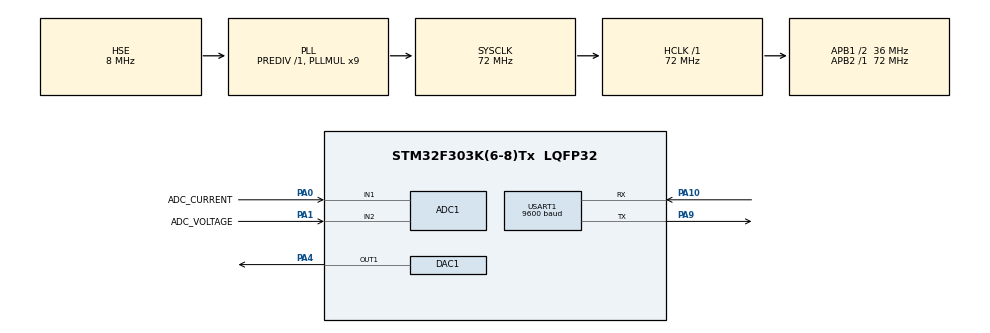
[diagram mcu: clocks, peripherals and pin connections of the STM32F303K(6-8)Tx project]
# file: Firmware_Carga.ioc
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ADC1.Channel-0\#ChannelRegularConversion=ADC_CHANNEL_1
ADC1.Channel-1\#ChannelRegularConversion=ADC_CHANNEL_2
ADC1.DMAContinuousRequests=ENABLE
ADC1.EnableInjectedConversion=DISABLE
ADC1.ExternalTrigConv=ADC_EXTERNALTRIGCONV_T1_TRGO
ADC1.NbrOfConversion=2
ADC1.NbrOfConversionFlag=1
ADC1.Offset-0\#ChannelRegularConversion=0
ADC1.Offset-1\#ChannelRegularConversion=0
ADC1.OffsetNumber-0\#ChannelRegularConversion=ADC_OFFSET_NONE
ADC1.OffsetNumber-1\#ChannelRegularConversion=ADC_OFFSET_NONE
ADC1.Rank-0\#ChannelRegularConversion=1
ADC1.Rank-1\#ChannelRegularConversion=2
ADC1.SamplingTime-0\#ChannelRegularConversion=ADC_SAMPLETIME_601CYCLES_5
ADC1.SamplingTime-1\#ChannelRegularConversion=ADC_SAMPLETIME_1CYCLE_5
ADC1.SamplingTimeOPAMP-1\#ChannelRegularConversion=ADC_SAMPLETIME_61CYCLES_5
ADC1.SubFamily=STM32F303x8
ADC1.master=1
DAC1.DAC_OutputBuffer=DAC_OUTPUTBUFFER_DISABLE
Dma.ADC1.0.Direction=DMA_PERIPH_TO_MEMORY
Dma.ADC1.0.Instance=DMA1_Channel1
Dma.ADC1.0.MemDataAlignment=DMA_MDATAALIGN_HALFWORD
Dma.ADC1.0.MemInc=DMA_MINC_ENABLE
Dma.ADC1.0.Mode=DMA_CIRCULAR
Dma.ADC1.0.PeriphDataAlignment=DMA_PDATAALIGN_HALFWORD
Dma.ADC1.0.PeriphInc=DMA_PINC_DISABLE
Dma.ADC1.0.Priority=DMA_PRIORITY_VERY_HIGH
Dma.Request0=ADC1
Mcu.Family=STM32F3
Mcu.Name=STM32F303K(6-8)Tx
Mcu.Package=LQFP32
NVIC.DMA1_Channel1_IRQn=true\:0\:0\:false\:false\:true\:false\:true
NVIC.PriorityGroup=NVIC_PRIORITYGROUP_4
PA0.GPIO_Label=ADC_CURRENT
PA0.Mode=IN1-Single-Ended
PA0.Signal=ADC1_IN1
PA1.GPIO_Label=ADC_VOLTAGE
PA1.Mode=IN2-Single-Ended
PA1.Signal=ADC1_IN2
PA10.Mode=Asynchronous
PA10.Signal=USART1_RX
PA13.Mode=Trace_Asynchronous_SW
PA13.Signal=SYS_JTMS-SWDIO
PA14.Mode=Trace_Asynchronous_SW
PA14.Signal=SYS_JTCK-SWCLK
PA4.Signal=COMP_DAC11_group
PA9.Mode=Asynchronous
PA9.Signal=USART1_TX
PB3.Mode=Trace_Asynchronous_SW
PB3.Signal=SYS_JTDO-TRACESWO
PF0\ /\ OSC_IN.Mode=HSE-External-Oscillator
PF0\ /\ OSC_IN.Signal=RCC_OSC_IN
PF1\ /\ OSC_OUT.Mode=HSE-External-Oscillator
PF1\ /\ OSC_OUT.Signal=RCC_OSC_OUT
ProjectManager.HeapSize=0x200
ProjectManager.StackSize=0x400
ProjectManager.TargetToolchain=EWARM V8
RCC.AHBFreq_Value=72000000
RCC.APB1CLKDivider=RCC_HCLK_DIV2
RCC.APB1Freq_Value=36000000
RCC.APB1TimFreq_Value=72000000
RCC.APB2Freq_Value=72000000
RCC.APB2TimFreq_Value=72000000
RCC.CortexFreq_Value=72000000
RCC.HCLKFreq_Value=72000000
RCC.HSE_VALUE=8000000
RCC.HSI_VALUE=8000000
RCC.PLLMUL=RCC_PLL_MUL9
RCC.PLLSourceVirtual=RCC_PLLSOURCE_HSE
RCC.SYSCLKFreq_VALUE=72000000
RCC.SYSCLKSourceVirtual=RCC_SYSCLKSOURCE_PLLCLK
SH.COMP_DAC11_group.0=DAC1_OUT1,DAC_OUT1
TIM1.Period=1
TIM1.Prescaler=720
TIM1.TIM_MasterOutputTrigger=TIM_TRGO_UPDATE
USART1.BaudRate=9600
USART1.Parity=PARITY_NONE
USART1.StopBits=STOPBITS_1
USART1.VirtualMode-Asynchronous=VM_ASYNC
USART1.WordLength=WORDLENGTH_8B
VP_TIM1_VS_ClockSourceINT.Mode=Internal
board=custom

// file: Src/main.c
/* USER CODE BEGIN Header */
/**
  ******************************************************************************
  * @file           : main.c
  * @brief          : Main program body
  ******************************************************************************
  * @attention
  *
  * <h2><center>&copy; Copyright (c) 2021 STMicroelectronics.
  * All rights reserved.</center></h2>
  *
  * This software component is licensed by ST under BSD 3-Clause license,
  * the "License"; You may not use this file except in compliance with the
  * License. You may obtain a copy of the License at:
  *                        opensource.org/licenses/BSD-3-Clause
  *
  ******************************************************************************
  */

/**

  ******************************************************************************
   *CORRENTE M�XIMA LIMITADA PELO DAC = 3.3 A
  ******************************************************************************

*/

/* USER CODE END Header */
#include "main.h"

/* USER CODE BEGIN Includes */
#include "stdbool.h"

/* USER CODE END Includes */

ADC_HandleTypeDef hadc1;
DMA_HandleTypeDef hdma_adc1;

DAC_HandleTypeDef hdac1;

TIM_HandleTypeDef htim1;

UART_HandleTypeDef huart1;

void SystemClock_Config(void);
static void MX_GPIO_Init(void);
static void MX_ADC1_Init(void);
static void MX_DAC1_Init(void);
static void MX_DMA_Init(void);
static void MX_USART1_UART_Init(void);
static void MX_TIM1_Init(void);

/* USER CODE BEGIN 0 */

E_Carga_State Carga_State = CURRENT;

uint16_t ADC_VALUES[2];

float current_Value_A = 0.25;
float potency_Value_W = 0;
float resistance_Value_Ohms = 0;

/* USER CODE END 0 */

int main(void)
{

  /* MCU Configuration--------------------------------------------------------*/

  /* Reset of all peripherals, Initializes the Flash interface and the Systick. */
  HAL_Init();

  /* Configure the system clock */
  SystemClock_Config();

  /* USER CODE BEGIN SysInit */
  MX_DMA_Init();
  /* USER CODE END SysInit */

  /* Initialize all configured peripherals */
  MX_GPIO_Init();
  MX_ADC1_Init();
  MX_DAC1_Init();
  MX_DMA_Init();
  MX_USART1_UART_Init();
  MX_TIM1_Init();
  /* USER CODE BEGIN 2 */

  HAL_ADCEx_Calibration_Start(&hadc1, ADC_SINGLE_ENDED);
  HAL_TIM_Base_Start(&htim1);
  HAL_ADC_Start_DMA(&hadc1, (uint32_t*) ADC_VALUES, 2);

  Load_State_Machine_Init();

  /* USER CODE END 2 */

  /* Infinite loop */
  /* USER CODE BEGIN WHILE */
  while (1)
  {
    /* PARA DEBUG IAR*/
    /*
    Load_State_Machine(Carga_State);

    set_Current_Value(current_Value_A);

    set_Potency_Value(potency_Value_W);

    set_Resistance_Value(resistance_Value_Ohms);
    */

    Load_State_Machine();

    /* USER CODE END WHILE */

  }
}

void SystemClock_Config(void)
{
  RCC_OscInitTypeDef RCC_OscInitStruct = {0};
  RCC_ClkInitTypeDef RCC_ClkInitStruct = {0};
  RCC_PeriphCLKInitTypeDef PeriphClkInit = {0};

  /** Initializes the RCC Oscillators according to the specified parameters
  * in the RCC_OscInitTypeDef structure.
  */
  RCC_OscInitStruct.OscillatorType = RCC_OSCILLATORTYPE_HSE;
  RCC_OscInitStruct.HSEState = RCC_HSE_ON;
  RCC_OscInitStruct.HSEPredivValue = RCC_HSE_PREDIV_DIV1;
  RCC_OscInitStruct.HSIState = RCC_HSI_ON;
  RCC_OscInitStruct.PLL.PLLState = RCC_PLL_ON;
  RCC_OscInitStruct.PLL.PLLSource = RCC_PLLSOURCE_HSE;
  RCC_OscInitStruct.PLL.PLLMUL = RCC_PLL_MUL9;
  if (HAL_RCC_OscConfig(&RCC_OscInitStruct) != HAL_OK)
  {
    Error_Handler();
  }
  /** Initializes the CPU, AHB and APB buses clocks
  */
  RCC_ClkInitStruct.ClockType = RCC_CLOCKTYPE_HCLK|RCC_CLOCKTYPE_SYSCLK
                              |RCC_CLOCKTYPE_PCLK1|RCC_CLOCKTYPE_PCLK2;
  RCC_ClkInitStruct.SYSCLKSource = RCC_SYSCLKSOURCE_PLLCLK;
  RCC_ClkInitStruct.AHBCLKDivider = RCC_SYSCLK_DIV1;
  RCC_ClkInitStruct.APB1CLKDivider = RCC_HCLK_DIV2;
  RCC_ClkInitStruct.APB2CLKDivider = RCC_HCLK_DIV1;

  if (HAL_RCC_ClockConfig(&RCC_ClkInitStruct, FLASH_LATENCY_2) != HAL_OK)
  {
    Error_Handler();
  }
  PeriphClkInit.PeriphClockSelection = RCC_PERIPHCLK_USART1|RCC_PERIPHCLK_TIM1
                              |RCC_PERIPHCLK_ADC12;
  PeriphClkInit.Usart1ClockSelection = RCC_USART1CLKSOURCE_PCLK1;
  PeriphClkInit.Adc12ClockSelection = RCC_ADC12PLLCLK_DIV1;
  PeriphClkInit.Tim1ClockSelection = RCC_TIM1CLK_HCLK;
  if (HAL_RCCEx_PeriphCLKConfig(&PeriphClkInit) != HAL_OK)
  {
    Error_Handler();
  }
}

static void MX_ADC1_Init(void)
{

  ADC_MultiModeTypeDef multimode = {0};
  ADC_ChannelConfTypeDef sConfig = {0};

  /** Common config
  */
  hadc1.Instance = ADC1;
  hadc1.Init.ClockPrescaler = ADC_CLOCK_ASYNC_DIV1;
  hadc1.Init.Resolution = ADC_RESOLUTION_12B;
  hadc1.Init.ScanConvMode = ADC_SCAN_ENABLE;
  hadc1.Init.ContinuousConvMode = DISABLE;
  hadc1.Init.DiscontinuousConvMode = DISABLE;
  hadc1.Init.ExternalTrigConvEdge = ADC_EXTERNALTRIGCONVEDGE_RISING;
  hadc1.Init.ExternalTrigConv = ADC_EXTERNALTRIGCONV_T1_TRGO;
  hadc1.Init.DataAlign = ADC_DATAALIGN_RIGHT;
  hadc1.Init.NbrOfConversion = 2;
  hadc1.Init.DMAContinuousRequests = ENABLE;
  hadc1.Init.EOCSelection = ADC_EOC_SINGLE_CONV;
  hadc1.Init.LowPowerAutoWait = DISABLE;
  hadc1.Init.Overrun = ADC_OVR_DATA_OVERWRITTEN;
  if (HAL_ADC_Init(&hadc1) != HAL_OK)
  {
    Error_Handler();
  }
  /** Configure the ADC multi-mode
  */
  multimode.Mode = ADC_MODE_INDEPENDENT;
  if (HAL_ADCEx_MultiModeConfigChannel(&hadc1, &multimode) != HAL_OK)
  {
    Error_Handler();
  }
  /** Configure Regular Channel
  */
  sConfig.Channel = ADC_CHANNEL_1;
  sConfig.Rank = ADC_REGULAR_RANK_1;
  sConfig.SingleDiff = ADC_SINGLE_ENDED;
  sConfig.SamplingTime = ADC_SAMPLETIME_601CYCLES_5;
  sConfig.OffsetNumber = ADC_OFFSET_NONE;
  sConfig.Offset = 0;
  if (HAL_ADC_ConfigChannel(&hadc1, &sConfig) != HAL_OK)
  {
    Error_Handler();
  }
  /** Configure Regular Channel
  */
  sConfig.Channel = ADC_CHANNEL_2;
  sConfig.Rank = ADC_REGULAR_RANK_2;
  sConfig.SamplingTime = ADC_SAMPLETIME_1CYCLE_5;
  if (HAL_ADC_ConfigChannel(&hadc1, &sConfig) != HAL_OK)
  {
    Error_Handler();
  }

}

static void MX_DAC1_Init(void)
{

  DAC_ChannelConfTypeDef sConfig = {0};

  /** DAC Initialization
  */
  hdac1.Instance = DAC1;
  if (HAL_DAC_Init(&hdac1) != HAL_OK)
  {
    Error_Handler();
  }
  /** DAC channel OUT1 config
  */
  sConfig.DAC_Trigger = DAC_TRIGGER_NONE;
  sConfig.DAC_OutputBuffer = DAC_OUTPUTBUFFER_DISABLE;
  if (HAL_DAC_ConfigChannel(&hdac1, &sConfig, DAC_CHANNEL_1) != HAL_OK)
  {
    Error_Handler();
  }

}

static void MX_TIM1_Init(void)
{

  TIM_ClockConfigTypeDef sClockSourceConfig = {0};
  TIM_MasterConfigTypeDef sMasterConfig = {0};

  htim1.Instance = TIM1;
  htim1.Init.Prescaler = 720;
  htim1.Init.CounterMode = TIM_COUNTERMODE_UP;
  htim1.Init.Period = 1;
  htim1.Init.ClockDivision = TIM_CLOCKDIVISION_DIV1;
  htim1.Init.RepetitionCounter = 0;
  htim1.Init.AutoReloadPreload = TIM_AUTORELOAD_PRELOAD_DISABLE;
  if (HAL_TIM_Base_Init(&htim1) != HAL_OK)
  {
    Error_Handler();
  }
  sClockSourceConfig.ClockSource = TIM_CLOCKSOURCE_INTERNAL;
  if (HAL_TIM_ConfigClockSource(&htim1, &sClockSourceConfig) != HAL_OK)
  {
    Error_Handler();
  }
  sMasterConfig.MasterOutputTrigger = TIM_TRGO_UPDATE;
  sMasterConfig.MasterOutputTrigger2 = TIM_TRGO2_RESET;
  sMasterConfig.MasterSlaveMode = TIM_MASTERSLAVEMODE_DISABLE;
  if (HAL_TIMEx_MasterConfigSynchronization(&htim1, &sMasterConfig) != HAL_OK)
  {
    Error_Handler();
  }

}

static void MX_USART1_UART_Init(void)
{

  huart1.Instance = USART1;
  huart1.Init.BaudRate = 9600;
  huart1.Init.WordLength = UART_WORDLENGTH_8B;
  huart1.Init.StopBits = UART_STOPBITS_1;
  huart1.Init.Parity = UART_PARITY_NONE;
  huart1.Init.Mode = UART_MODE_TX_RX;
  huart1.Init.HwFlowCtl = UART_HWCONTROL_NONE;
  huart1.Init.OverSampling = UART_OVERSAMPLING_16;
  huart1.Init.OneBitSampling = UART_ONE_BIT_SAMPLE_DISABLE;
  huart1.AdvancedInit.AdvFeatureInit = UART_ADVFEATURE_NO_INIT;
  if (HAL_UART_Init(&huart1) != HAL_OK)
  {
    Error_Handler();
  }

}

static void MX_DMA_Init(void)
{

  /* DMA controller clock enable */
  __HAL_RCC_DMA1_CLK_ENABLE();

  /* DMA interrupt init */
  /* DMA1_Channel1_IRQn interrupt configuration */
  HAL_NVIC_SetPriority(DMA1_Channel1_IRQn, 0, 0);
  HAL_NVIC_EnableIRQ(DMA1_Channel1_IRQn);

}

static void MX_GPIO_Init(void)
{

  /* GPIO Ports Clock Enable */
  __HAL_RCC_GPIOF_CLK_ENABLE();
  __HAL_RCC_GPIOA_CLK_ENABLE();
  __HAL_RCC_GPIOB_CLK_ENABLE();

}

void Error_Handler(void)
{
}
